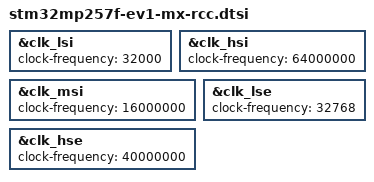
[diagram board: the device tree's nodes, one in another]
// SPDX-License-Identifier: (GPL-2.0-only OR BSD-3-Clause)
/*
 * Copyright (C) 2026, STMicroelectronics - All Rights Reserved
 * Author: STM32CubeMX code generation for STMicroelectronics.
 */

/* For more information on Device Tree configuration, please refer to
 * https://wiki.st.com/stm32mpu/wiki/Category:Device_tree_configuration
 */

&clk_lsi {
	clock-frequency = <32000>;

	/* USER CODE BEGIN clk_lsi */
	/* USER CODE END clk_lsi */
};
&clk_hsi {
	clock-frequency = <64000000>;

	/* USER CODE BEGIN clk_hsi */
	/* USER CODE END clk_hsi */
};
&clk_msi {
	clock-frequency = <16000000>;

	/* USER CODE BEGIN clk_msi */
	/* USER CODE END clk_msi */
};
&clk_lse {
	clock-frequency = <32768>;

	/* USER CODE BEGIN clk_lse */
	/* USER CODE END clk_lse */
};
&clk_hse {
	clock-frequency = <40000000>;

	/* USER CODE BEGIN clk_hse */
	/* USER CODE END clk_hse */
};

